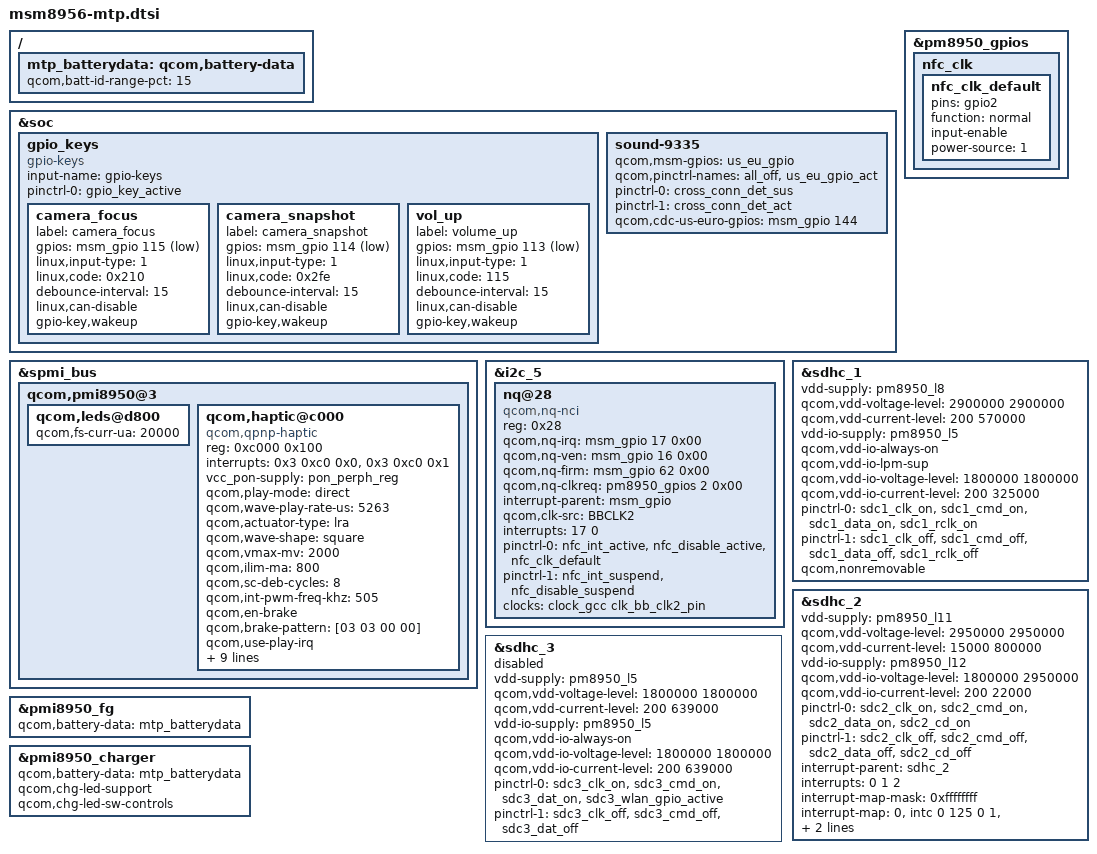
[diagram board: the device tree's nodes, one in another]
// SPDX-License-Identifier: GPL-2.0
// Copyright (c) 2015-2016, The Linux Foundation. All rights reserved.
// Copyright (c) 2022, Benarji Anand <benarji385@gmail.com>

#include <dt-bindings/gpio/gpio.h>
#include <dt-bindings/clock/qcom,gcc-msm8956.h>
#include "msm8956-camera-sensor-mtp.dtsi"
#include "msm8956-mdss-panels.dtsi"

&soc {
	gpio_keys {
		compatible = "gpio-keys";
		input-name = "gpio-keys";
		pinctrl-names = "default";
		pinctrl-0 = <&gpio_key_active>;

		camera_focus {
			label = "camera_focus";
			gpios = <&msm_gpio 115 0x1>;
			linux,input-type = <1>;
			linux,code = <0x210>;
			debounce-interval = <15>;
			linux,can-disable;
			gpio-key,wakeup;

		};

		camera_snapshot {
			label = "camera_snapshot";
			gpios = <&msm_gpio 114 0x1>;
			linux,input-type = <1>;
			linux,code = <0x2fe>;
			debounce-interval = <15>;
			linux,can-disable;
			gpio-key,wakeup;

		};

		vol_up {
			label = "volume_up";
			gpios = <&msm_gpio 113 0x1>;
			linux,input-type = <1>;
			linux,code = <115>;
			debounce-interval = <15>;
			linux,can-disable;
                        gpio-key,wakeup;
		};
	};

	sound-9335 {
		qcom,msm-gpios =
			"us_eu_gpio";
		qcom,pinctrl-names =
			"all_off",
			"us_eu_gpio_act";
		pinctrl-names =
			"all_off",
			"us_eu_gpio_act";
		pinctrl-0 = <&cross_conn_det_sus>;
		pinctrl-1 = <&cross_conn_det_act>;
		qcom,cdc-us-euro-gpios = <&msm_gpio 144 0>;
	};
};

#if 0
&blsp1_uart2 {
	status = "ok";
	pinctrl-names = "default";
	pinctrl-0 = <&uart_console_sleep>;
};
#endif

&spmi_bus {
	qcom,pmi8950@3 {
		qcom,leds@d800 {
			qcom,fs-curr-ua = <20000>;
		};

		qcom,haptic@c000 {
			compatible = "qcom,qpnp-haptic";
			reg = <0xc000 0x100>;
			interrupts = <0x3 0xc0 0x0>,
				<0x3 0xc0 0x1>;
			interrupt-names = "sc-irq", "play-irq";
			vcc_pon-supply = <&pon_perph_reg>;
			qcom,play-mode = "direct";
			qcom,wave-play-rate-us = <5263>;
			qcom,actuator-type = "lra";
			qcom,wave-shape = "square";
			qcom,vmax-mv = <2000>;
			qcom,ilim-ma = <800>;
			qcom,sc-deb-cycles = <8>;
			qcom,int-pwm-freq-khz = <505>;
			qcom,en-brake;
			qcom,brake-pattern = [03 03 00 00];
			qcom,use-play-irq;
			qcom,use-sc-irq;
			qcom,wave-samples = [3e 3e 3e 3e 3e 3e 3e 3e];
			qcom,wave-rep-cnt = <1>;
			qcom,wave-samp-rep-cnt = <1>;
			qcom,lra-auto-res-mode="qwd";
			qcom,lra-high-z="opt1";
			qcom,lra-res-cal-period = <4>;
			qcom,correct-lra-drive-freq;
			qcom,misc-trim-error-rc19p2-clk-reg-present;
		};
	};
};

&pm8950_gpios {
	nfc_clk {
		nfc_clk_default: nfc_clk_default {
			pins = "gpio2";
			function = "normal";
			input-enable;
			power-source = <1>;
		};
	};
};

&i2c_5 { /* BLSP2 QUP1 (NFC) */
	status = "ok";
	nq@28 {
		compatible = "qcom,nq-nci";
		reg = <0x28>;
		qcom,nq-irq = <&msm_gpio 17 0x00>;
		qcom,nq-ven = <&msm_gpio 16 0x00>;
		qcom,nq-firm = <&msm_gpio 62 0x00>;
		qcom,nq-clkreq = <&pm8950_gpios 2 0x00>;
		interrupt-parent = <&msm_gpio>;
		qcom,clk-src = "BBCLK2";
		interrupts = <17 0>;
		interrupt-names = "nfc_irq";
		pinctrl-names = "nfc_active", "nfc_suspend";
		pinctrl-0 = <&nfc_int_active &nfc_disable_active
						&nfc_clk_default>;
		pinctrl-1 = <&nfc_int_suspend &nfc_disable_suspend>;
		clocks = <&clock_gcc clk_bb_clk2_pin>;
		clock-names = "ref_clk";
	};
};

&sdhc_1 {
	vdd-supply = <&pm8950_l8>;
	qcom,vdd-voltage-level = <2900000 2900000>;
	qcom,vdd-current-level = <200 570000>;

	vdd-io-supply = <&pm8950_l5>;
	qcom,vdd-io-always-on;
	qcom,vdd-io-lpm-sup;
	qcom,vdd-io-voltage-level = <1800000 1800000>;
	qcom,vdd-io-current-level = <200 325000>;

	pinctrl-names = "active", "sleep";
	pinctrl-0 = <&sdc1_clk_on &sdc1_cmd_on &sdc1_data_on &sdc1_rclk_on>;
	pinctrl-1 = <&sdc1_clk_off &sdc1_cmd_off &sdc1_data_off &sdc1_rclk_off>;

	qcom,nonremovable;

	status = "ok";
};

&sdhc_2 {
	vdd-supply = <&pm8950_l11>;
	qcom,vdd-voltage-level = <2950000 2950000>;
	qcom,vdd-current-level = <15000 800000>;

	vdd-io-supply = <&pm8950_l12>;
	qcom,vdd-io-voltage-level = <1800000 2950000>;
	qcom,vdd-io-current-level = <200 22000>;

	pinctrl-names = "active", "sleep";
	pinctrl-0 = <&sdc2_clk_on &sdc2_cmd_on &sdc2_data_on &sdc2_cd_on>;
	pinctrl-1 = <&sdc2_clk_off &sdc2_cmd_off &sdc2_data_off &sdc2_cd_off>;

	#address-cells = <0>;
	interrupt-parent = <&sdhc_2>;
	interrupts = <0 1 2>;
	#interrupt-cells = <1>;
	interrupt-map-mask = <0xffffffff>;
	interrupt-map = <0 &intc 0 125 0
			1 &intc 0 221 0
			2 &msm_gpio 100 0>;
	interrupt-names = "hc_irq", "pwr_irq", "status_irq";
	cd-gpios = <&msm_gpio 100 0x1>;

	status = "ok";
};

&sdhc_3 {
	vdd-supply = <&pm8950_l5>;
	qcom,vdd-voltage-level = <1800000 1800000>;
	qcom,vdd-current-level = <200 639000>;

	vdd-io-supply = <&pm8950_l5>;
	qcom,vdd-io-always-on;
	qcom,vdd-io-voltage-level = <1800000 1800000>;
	qcom,vdd-io-current-level = <200 639000>;

	pinctrl-names = "active", "sleep";
	pinctrl-0 = <&sdc3_clk_on &sdc3_cmd_on &sdc3_dat_on
					&sdc3_wlan_gpio_active>;
	pinctrl-1 = <&sdc3_clk_off &sdc3_cmd_off &sdc3_dat_off>;

	status = "disabled";
};

/{
	mtp_batterydata: qcom,battery-data {
		qcom,batt-id-range-pct = <15>;
		#include "batterydata-itech-3000mah.dtsi"
		#include "batterydata-ascent-3450mAh.dtsi"
	};
};

&pmi8950_fg {
	qcom,battery-data = <&mtp_batterydata>;
};

&pmi8950_charger {
	qcom,battery-data = <&mtp_batterydata>;
	qcom,chg-led-support;
	qcom,chg-led-sw-controls;
};
